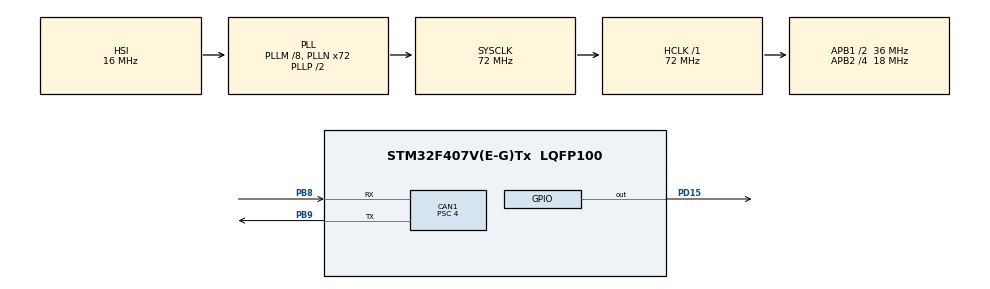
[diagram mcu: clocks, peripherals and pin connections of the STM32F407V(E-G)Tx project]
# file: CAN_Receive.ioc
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CAN1.BS1=CAN_BS1_12TQ
CAN1.BS2=CAN_BS2_5TQ
CAN1.CalculateTimeBit=2000
CAN1.CalculateTimeQuantum=111.11111111111111
CAN1.Prescaler=4
CAN1.SJW=CAN_SJW_2TQ
Mcu.Family=STM32F4
Mcu.Name=STM32F407V(E-G)Tx
Mcu.Package=LQFP100
NVIC.CAN1_RX0_IRQn=true\:0\:0\:false\:false\:true
NVIC.CAN1_RX1_IRQn=true\:0\:0\:false\:false\:true
NVIC.CAN1_SCE_IRQn=true\:0\:0\:false\:false\:true
NVIC.CAN1_TX_IRQn=true\:0\:0\:false\:false\:true
NVIC.PriorityGroup=NVIC_PRIORITYGROUP_0
PB8.Mode=Master
PB8.Signal=CAN1_RX
PB9.Mode=Master
PB9.Signal=CAN1_TX
PD15.Signal=GPIO_Output
ProjectManager.HeapSize=0x200
ProjectManager.StackSize=0x400
ProjectManager.TargetToolchain=MDK-ARM V4
RCC.48MHZClocksFreq_Value=20571428.57142857
RCC.AHBCLKDivider=RCC_SYSCLK_DIV1
RCC.AHBFreq_Value=72000000
RCC.APB1CLKDivider=RCC_HCLK_DIV2
RCC.APB1Freq_Value=36000000
RCC.APB1TimFreq_Value=72000000
RCC.APB2CLKDivider=RCC_HCLK_DIV4
RCC.APB2Freq_Value=18000000
RCC.APB2TimFreq_Value=36000000
RCC.ClockTypeHCLK=RCC_CLOCKTYPE_HCLK
RCC.ClockTypePCLK1=RCC_CLOCKTYPE_PCLK1
RCC.ClockTypePCLK2=RCC_CLOCKTYPE_PCLK2
RCC.ClockTypeSysClk=RCC_CLOCKTYPE_SYSCLK
RCC.CortexFreq_Value=72000000
RCC.EnableExtClockForI2S=false
RCC.EnableHSE=false
RCC.EnableHSERTCDevisor=false
RCC.EnableLSE=false
RCC.EnableLSERTC=false
RCC.ExtClockEnable=false
RCC.HCLKFreq_Value=72000000
RCC.HSEState=RCC_HSE_OFF
RCC.HSE_VALUE=8000000
RCC.HSIState=RCC_HSI_ON
RCC.HSI_VALUE=16000000
RCC.I2SEnable=false
RCC.IWDGEnable=false
RCC.LSE_VALUE=32768
RCC.LSIState=RCC_LSI_OFF
RCC.MCO1OutPutEnable=false
RCC.MCO2OutPutEnable=false
RCC.OscillatorTypeHSI=RCC_OSCILLATORTYPE_HSI
RCC.PLLM=8
RCC.PLLN=72
RCC.PLLP=RCC_PLLP_DIV2
RCC.PLLQ=7
RCC.PLLSource=RCC_PLLSOURCE_HSI
RCC.PLLSourceVirtual=RCC_PLLSOURCE_HSI
RCC.PLLState=RCC_PLL_ON
RCC.RNGEnable=false
RCC.RTCEnable=false
RCC.SDIOEnable=false
RCC.SYSCLKFreq_VALUE=72000000
RCC.SYSCLKSource=RCC_SYSCLKSOURCE_PLLCLK
RCC.USBFSEnable=false
RCC.USBHSEnable=false
RCC.VCOOutputFreq_Value=144000000
board=STM32F4DISCOVERY

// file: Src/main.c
/**
  ******************************************************************************
  * File Name          : main.c
  * Description        : Main program body
  ******************************************************************************
  *
  * COPYRIGHT(c) 2017 STMicroelectronics
  *
  * Redistribution and use in source and binary forms, with or without modification,
  * are permitted provided that the following conditions are met:
  *   1. Redistributions of source code must retain the above copyright notice,
  *      this list of conditions and the following disclaimer.
  *   2. Redistributions in binary form must reproduce the above copyright notice,
  *      this list of conditions and the following disclaimer in the documentation
  *      and/or other materials provided with the distribution.
  *   3. Neither the name of STMicroelectronics nor the names of its contributors
  *      may be used to endorse or promote products derived from this software
  *      without specific prior written permission.
  *
  * THIS SOFTWARE IS PROVIDED BY THE COPYRIGHT HOLDERS AND CONTRIBUTORS "AS IS"
  * AND ANY EXPRESS OR IMPLIED WARRANTIES, INCLUDING, BUT NOT LIMITED TO, THE
  * IMPLIED WARRANTIES OF MERCHANTABILITY AND FITNESS FOR A PARTICULAR PURPOSE ARE
  * DISCLAIMED. IN NO EVENT SHALL THE COPYRIGHT HOLDER OR CONTRIBUTORS BE LIABLE
  * FOR ANY DIRECT, INDIRECT, INCIDENTAL, SPECIAL, EXEMPLARY, OR CONSEQUENTIAL
  * DAMAGES (INCLUDING, BUT NOT LIMITED TO, PROCUREMENT OF SUBSTITUTE GOODS OR
  * SERVICES; LOSS OF USE, DATA, OR PROFITS; OR BUSINESS INTERRUPTION) HOWEVER
  * CAUSED AND ON ANY THEORY OF LIABILITY, WHETHER IN CONTRACT, STRICT LIABILITY,
  * OR TORT (INCLUDING NEGLIGENCE OR OTHERWISE) ARISING IN ANY WAY OUT OF THE USE
  * OF THIS SOFTWARE, EVEN IF ADVISED OF THE POSSIBILITY OF SUCH DAMAGE.
  *
  ******************************************************************************
  */
#include "main.h"
#include "stm32f4xx_hal.h"

CAN_HandleTypeDef hcan1;

/* USER CODE BEGIN PV */
/* Private variables ---------------------------------------------------------*/

/* USER CODE END PV */

void SystemClock_Config(void);
void Error_Handler(void);
static void MX_GPIO_Init(void);
static void MX_CAN1_Init(void);

/* USER CODE BEGIN PFP */
/* Private function prototypes -----------------------------------------------*/

/* USER CODE END PFP */

/* USER CODE BEGIN 0 */

void blink()
{
		HAL_GPIO_TogglePin(GPIOD, GPIO_PIN_15);
		int i=0;
		while(i<2000000)
		{
			i++;
		}
		HAL_GPIO_TogglePin(GPIOD, GPIO_PIN_15);
}

void HAL_CAN_RxCpltCallback(CAN_HandleTypeDef *CanHandle) {

	if(CanHandle->pRxMsg->StdId == 0x0)
	{
		 blink();
	}

	if(CanHandle->State == HAL_CAN_STATE_BUSY_TX)
	{
	  CanHandle->State = HAL_CAN_STATE_BUSY_TX_RX0;
	}
	else
		{
	  CanHandle->State = HAL_CAN_STATE_BUSY_RX0;

		/* Set CAN error code to none */
		CanHandle->ErrorCode = HAL_CAN_ERROR_NONE;

		/* Enable Error warning Interrupt */
		__HAL_CAN_ENABLE_IT(CanHandle, CAN_IT_EWG);

		/* Enable Error passive Interrupt */
		__HAL_CAN_ENABLE_IT(CanHandle, CAN_IT_EPV);

		/* Enable Bus-off Interrupt */
		__HAL_CAN_ENABLE_IT(CanHandle, CAN_IT_BOF);

		/* Enable Last error code Interrupt */
		__HAL_CAN_ENABLE_IT(CanHandle, CAN_IT_LEC);

		/* Enable Error Interrupt */
		__HAL_CAN_ENABLE_IT(CanHandle, CAN_IT_ERR);
	  }

	  // Enable FIFO 0 message pending Interrupt
	  __HAL_CAN_ENABLE_IT(CanHandle, CAN_IT_FMP0);
}

/* USER CODE END 0 */

int main(void)
{

  /* MCU Configuration----------------------------------------------------------*/

  /* Reset of all peripherals, Initializes the Flash interface and the Systick. */
  HAL_Init();

  /* Configure the system clock */
  SystemClock_Config();

  /* Initialize all configured peripherals */
  MX_GPIO_Init();
  MX_CAN1_Init();

  /* USER CODE BEGIN 2 */
	if(HAL_CAN_Receive_IT(&hcan1, CAN_FIFO0) != HAL_OK) {
	  Error_Handler();
  }
  /* USER CODE END 2 */

  /* Infinite loop */
  while (1)
  {

  }

}

/** System Clock Configuration
*/
void SystemClock_Config(void)
{

  RCC_OscInitTypeDef RCC_OscInitStruct;
  RCC_ClkInitTypeDef RCC_ClkInitStruct;

    /**Configure the main internal regulator output voltage
    */
  __HAL_RCC_PWR_CLK_ENABLE();

  __HAL_PWR_VOLTAGESCALING_CONFIG(PWR_REGULATOR_VOLTAGE_SCALE1);

    /**Initializes the CPU, AHB and APB busses clocks
    */
  RCC_OscInitStruct.OscillatorType = RCC_OSCILLATORTYPE_HSI;
  RCC_OscInitStruct.HSIState = RCC_HSI_ON;
  RCC_OscInitStruct.HSICalibrationValue = 16;
  RCC_OscInitStruct.PLL.PLLState = RCC_PLL_ON;
  RCC_OscInitStruct.PLL.PLLSource = RCC_PLLSOURCE_HSI;
  RCC_OscInitStruct.PLL.PLLM = 8;
  RCC_OscInitStruct.PLL.PLLN = 72;
  RCC_OscInitStruct.PLL.PLLP = RCC_PLLP_DIV2;
  RCC_OscInitStruct.PLL.PLLQ = 7;
  if (HAL_RCC_OscConfig(&RCC_OscInitStruct) != HAL_OK)
  {
    Error_Handler();
  }

    /**Initializes the CPU, AHB and APB busses clocks
    */
  RCC_ClkInitStruct.ClockType = RCC_CLOCKTYPE_HCLK|RCC_CLOCKTYPE_SYSCLK
                              |RCC_CLOCKTYPE_PCLK1|RCC_CLOCKTYPE_PCLK2;
  RCC_ClkInitStruct.SYSCLKSource = RCC_SYSCLKSOURCE_PLLCLK;
  RCC_ClkInitStruct.AHBCLKDivider = RCC_SYSCLK_DIV1;
  RCC_ClkInitStruct.APB1CLKDivider = RCC_HCLK_DIV2;
  RCC_ClkInitStruct.APB2CLKDivider = RCC_HCLK_DIV4;

  if (HAL_RCC_ClockConfig(&RCC_ClkInitStruct, FLASH_LATENCY_2) != HAL_OK)
  {
    Error_Handler();
  }

    /**Configure the Systick interrupt time
    */
  HAL_SYSTICK_Config(HAL_RCC_GetHCLKFreq()/1000);

    /**Configure the Systick
    */
  HAL_SYSTICK_CLKSourceConfig(SYSTICK_CLKSOURCE_HCLK);

  /* SysTick_IRQn interrupt configuration */
  HAL_NVIC_SetPriority(SysTick_IRQn, 0, 0);
}

/* CAN1 init function */
static void MX_CAN1_Init(void)
{
	static CanRxMsgTypeDef CanRX;
	CAN_FilterConfTypeDef sFilterConfig;
	hcan1.pRxMsg = &CanRX;

  hcan1.Instance = CAN1;
  hcan1.Init.Prescaler = 4;
  hcan1.Init.Mode = CAN_MODE_NORMAL;
  hcan1.Init.SJW = CAN_SJW_2TQ;
  hcan1.Init.BS1 = CAN_BS1_12TQ;
  hcan1.Init.BS2 = CAN_BS2_5TQ;
  hcan1.Init.TTCM = DISABLE;
  hcan1.Init.ABOM = DISABLE;
  hcan1.Init.AWUM = DISABLE;
  hcan1.Init.NART = DISABLE;
  hcan1.Init.RFLM = DISABLE;
  hcan1.Init.TXFP = DISABLE;

  if (HAL_CAN_Init(&hcan1) != HAL_OK)
  {
    Error_Handler();
  }
	sFilterConfig.FilterNumber = 0;
	sFilterConfig.FilterMode = CAN_FILTERMODE_IDMASK;
	sFilterConfig.FilterScale = CAN_FILTERSCALE_32BIT;
	sFilterConfig.FilterIdHigh = 0x0000;
	sFilterConfig.FilterIdLow = 0x0000;
	sFilterConfig.FilterMaskIdHigh = 0x0000;
	sFilterConfig.FilterMaskIdLow = 0x0000;
	sFilterConfig.FilterFIFOAssignment = CAN_FILTER_FIFO0;
	sFilterConfig.FilterActivation = ENABLE;
	sFilterConfig.BankNumber = 14;

	if (HAL_CAN_ConfigFilter(&hcan1, &sFilterConfig) != HAL_OK)
	{
	/* Filter configuration Error */
	Error_Handler();
	}

}

/** Configure pins as
        * Analog
        * Input
        * Output
        * EVENT_OUT
        * EXTI
*/
static void MX_GPIO_Init(void)
{

  GPIO_InitTypeDef GPIO_InitStruct;

  /* GPIO Ports Clock Enable */
  __HAL_RCC_GPIOD_CLK_ENABLE();
  __HAL_RCC_GPIOB_CLK_ENABLE();

  /*Configure GPIO pin Output Level */
  HAL_GPIO_WritePin(GPIOD, GPIO_PIN_15, GPIO_PIN_RESET);

  /*Configure GPIO pin : PD15 */
  GPIO_InitStruct.Pin = GPIO_PIN_15;
  GPIO_InitStruct.Mode = GPIO_MODE_OUTPUT_PP;
  GPIO_InitStruct.Pull = GPIO_NOPULL;
  GPIO_InitStruct.Speed = GPIO_SPEED_FREQ_LOW;
  HAL_GPIO_Init(GPIOD, &GPIO_InitStruct);

}

void Error_Handler(void)
{
  while(1)
  {
  }
}

/************************ (C) COPYRIGHT STMicroelectronics *****END OF FILE****/
